# TEST register map
Vendor: rttsh test
ST-style minimal fixture: readAction=clear at register and field level
CPU: CM4 r0p1, little endian, no MPU, FPU, 4 interrupt priority bits
Registers are 32-bit, read-write, reset 0x0 unless marked. A register's access mark holds for its fields unless they carry their own. Offsets are from the block's base; lines under a group give offsets from that group; [hi:lo] are bit positions; {n}, {i} and the like mark numbered series; 'fields as' and 'values as' point back to an identical list; <NAME> marks a mode.

## Memory map
0x40000000 STAT — Status unit

## STAT — Status unit
Base 0x40000000
0x00 STATUS read-clears — Read-clears status
  [0] BUSY — Transfer busy
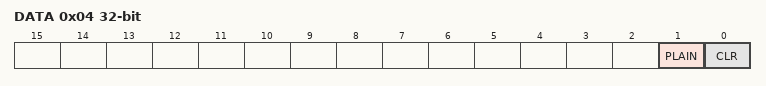
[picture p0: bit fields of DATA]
0x04 DATA — Data register with a clear-on-read field
  [1] PLAIN
  [0] CLR read-clears — Write 1 to clear
0x08 CTRL — Plain control register
  [0] EN — Enable
